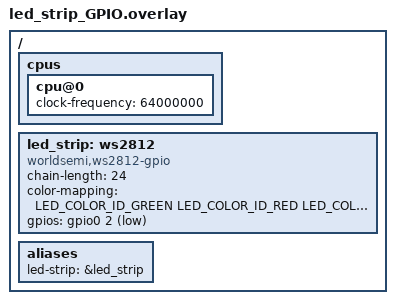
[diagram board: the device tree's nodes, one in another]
/*
 * Copyright (c) 2019, Nordic Semiconductor ASA
 *
 * SPDX-License-Identifier: Apache-2.0
 */

 #include <zephyr/dt-bindings/gpio/gpio.h>
 #include <zephyr/dt-bindings/led/led.h> 
 
 / {
    cpus {
        cpu@0 {
            clock-frequency = <64000000>;
        };
    };

     led_strip: ws2812 {
         compatible = "worldsemi,ws2812-gpio";
 
         chain-length = <24>; /* arbitrary */
         color-mapping = <LED_COLOR_ID_GREEN
                  LED_COLOR_ID_RED
                  LED_COLOR_ID_BLUE>;
         gpios = <&gpio0 2 1>;
     };
 
     aliases {
         led-strip = &led_strip;
     };
 };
